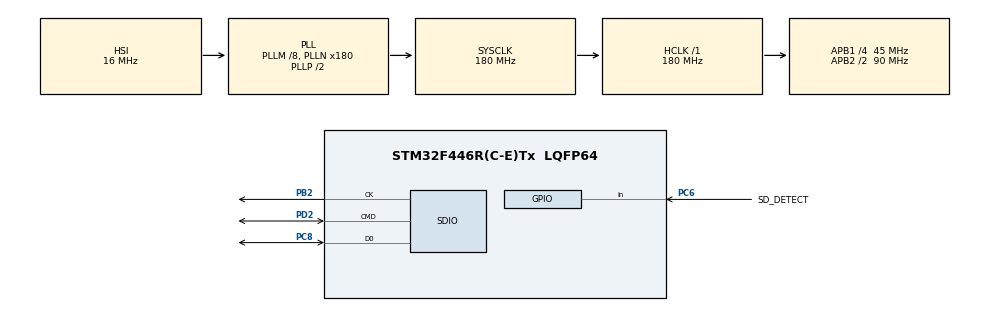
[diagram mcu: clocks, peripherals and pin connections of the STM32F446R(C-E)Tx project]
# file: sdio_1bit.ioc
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Dma.Request0=SDIO_RX
Dma.Request1=SDIO_TX
Dma.SDIO_RX.0.Direction=DMA_PERIPH_TO_MEMORY
Dma.SDIO_RX.0.FIFOMode=DMA_FIFOMODE_ENABLE
Dma.SDIO_RX.0.FIFOThreshold=DMA_FIFO_THRESHOLD_FULL
Dma.SDIO_RX.0.Instance=DMA2_Stream3
Dma.SDIO_RX.0.MemBurst=DMA_MBURST_INC4
Dma.SDIO_RX.0.MemDataAlignment=DMA_MDATAALIGN_WORD
Dma.SDIO_RX.0.MemInc=DMA_MINC_ENABLE
Dma.SDIO_RX.0.Mode=DMA_PFCTRL
Dma.SDIO_RX.0.PeriphBurst=DMA_PBURST_INC4
Dma.SDIO_RX.0.PeriphDataAlignment=DMA_PDATAALIGN_WORD
Dma.SDIO_RX.0.PeriphInc=DMA_PINC_DISABLE
Dma.SDIO_RX.0.Priority=DMA_PRIORITY_LOW
Dma.SDIO_TX.1.Direction=DMA_MEMORY_TO_PERIPH
Dma.SDIO_TX.1.FIFOMode=DMA_FIFOMODE_ENABLE
Dma.SDIO_TX.1.FIFOThreshold=DMA_FIFO_THRESHOLD_FULL
Dma.SDIO_TX.1.Instance=DMA2_Stream6
Dma.SDIO_TX.1.MemBurst=DMA_MBURST_INC4
Dma.SDIO_TX.1.MemDataAlignment=DMA_MDATAALIGN_WORD
Dma.SDIO_TX.1.MemInc=DMA_MINC_ENABLE
Dma.SDIO_TX.1.Mode=DMA_PFCTRL
Dma.SDIO_TX.1.PeriphBurst=DMA_PBURST_INC4
Dma.SDIO_TX.1.PeriphDataAlignment=DMA_PDATAALIGN_WORD
Dma.SDIO_TX.1.PeriphInc=DMA_PINC_DISABLE
Dma.SDIO_TX.1.Priority=DMA_PRIORITY_LOW
FATFS.BSP.number=1
FATFS._MAX_SS=4096
FATFS._USE_LFN=3
FATFS0.BSP.STBoard=false
FATFS0.BSP.api=Unknown
FATFS0.BSP.instance=PC6
FATFS0.BSP.ip=GPIO
FATFS0.BSP.mode=Input
FATFS0.BSP.name=Detect_SDIO
FATFS0.BSP.solution=PC6
Mcu.Family=STM32F4
Mcu.Name=STM32F446R(C-E)Tx
Mcu.Package=LQFP64
NVIC.DMA2_Stream3_IRQn=true\:0\:0\:false\:false\:true\:false\:true\:true
NVIC.DMA2_Stream6_IRQn=true\:0\:0\:false\:false\:true\:false\:true\:true
NVIC.PriorityGroup=NVIC_PRIORITYGROUP_4
PA13.Mode=Serial_Wire
PA13.Signal=SYS_JTMS-SWDIO
PA14.Mode=Serial_Wire
PA14.Signal=SYS_JTCK-SWCLK
PB2.Mode=SD_1_bit
PB2.Signal=SDIO_CK
PC6.GPIO_Label=SD_DETECT
PC6.GPIO_PuPd=GPIO_NOPULL
PC6.Signal=GPIO_Input
PC8.Mode=SD_1_bit
PC8.Signal=SDIO_D0
PD2.Mode=SD_1_bit
PD2.Signal=SDIO_CMD
ProjectManager.HeapSize=0x200
ProjectManager.StackSize=0x400
ProjectManager.TargetToolchain=STM32CubeIDE
RCC.AHBFreq_Value=180000000
RCC.APB1CLKDivider=RCC_HCLK_DIV4
RCC.APB1Freq_Value=45000000
RCC.APB1TimFreq_Value=90000000
RCC.APB2CLKDivider=RCC_HCLK_DIV2
RCC.APB2Freq_Value=90000000
RCC.APB2TimFreq_Value=180000000
RCC.CortexFreq_Value=180000000
RCC.HCLKFreq_Value=180000000
RCC.PLLM=8
RCC.PLLN=180
RCC.PLLQ=8
RCC.SYSCLKFreq_VALUE=180000000
RCC.SYSCLKSource=RCC_SYSCLKSOURCE_PLLCLK
RCC.USBFreq_Value=45000000
RCC.VCOOutputFreq_Value=360000000
SDIO.ClockDiv=10
VP_FATFS_VS_SDIO.Mode=SDIO
board=custom

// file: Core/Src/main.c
/* USER CODE BEGIN Header */
/**
  ******************************************************************************
  * @file           : main.c
  * @brief          : Main program body
  ******************************************************************************
  * @attention
  *
  * Copyright (c) 2024 STMicroelectronics.
  * All rights reserved.
  *
  * This software is licensed under terms that can be found in the LICENSE file
  * in the root directory of this software component.
  * If no LICENSE file comes with this software, it is provided AS-IS.
  *
  ******************************************************************************
  */
/* USER CODE END Header */
#include "main.h"
#include "fatfs.h"

/* USER CODE BEGIN Includes */
#include "stdio.h"
#include "sd.h"
/* USER CODE END Includes */

SD_HandleTypeDef hsd;
DMA_HandleTypeDef hdma_sdio_rx;
DMA_HandleTypeDef hdma_sdio_tx;

void SystemClock_Config(void);
static void MX_GPIO_Init(void);
static void MX_DMA_Init(void);
static void MX_SDIO_SD_Init(void);

/* USER CODE BEGIN 0 */
uint8_t buff[64];
/* USER CODE END 0 */

int main(void)
{

  /* MCU Configuration--------------------------------------------------------*/

  /* Reset of all peripherals, Initializes the Flash interface and the Systick. */
  HAL_Init();

  /* Configure the system clock */
  SystemClock_Config();

  /* Initialize all configured peripherals */
  MX_GPIO_Init();
  MX_DMA_Init();
  MX_SDIO_SD_Init();
  MX_FATFS_Init();
  /* USER CODE BEGIN 2 */
  sd_card_mount();
  sd_card_read("test.txt");
  sd_card_write("write.txt", "Joke, Cunning, and Revenge");
  sd_card_read("write.txt");
  sd_card_unmount();

  /* USER CODE END 2 */

  /* Infinite loop */
  while (1)
  {

  }
}

void SystemClock_Config(void)
{
  RCC_OscInitTypeDef RCC_OscInitStruct = {0};
  RCC_ClkInitTypeDef RCC_ClkInitStruct = {0};

  /** Configure the main internal regulator output voltage
  */
  __HAL_RCC_PWR_CLK_ENABLE();
  __HAL_PWR_VOLTAGESCALING_CONFIG(PWR_REGULATOR_VOLTAGE_SCALE1);

  /** Initializes the RCC Oscillators according to the specified parameters
  * in the RCC_OscInitTypeDef structure.
  */
  RCC_OscInitStruct.OscillatorType = RCC_OSCILLATORTYPE_HSI;
  RCC_OscInitStruct.HSIState = RCC_HSI_ON;
  RCC_OscInitStruct.HSICalibrationValue = RCC_HSICALIBRATION_DEFAULT;
  RCC_OscInitStruct.PLL.PLLState = RCC_PLL_ON;
  RCC_OscInitStruct.PLL.PLLSource = RCC_PLLSOURCE_HSI;
  RCC_OscInitStruct.PLL.PLLM = 8;
  RCC_OscInitStruct.PLL.PLLN = 180;
  RCC_OscInitStruct.PLL.PLLP = RCC_PLLP_DIV2;
  RCC_OscInitStruct.PLL.PLLQ = 8;
  RCC_OscInitStruct.PLL.PLLR = 2;
  if (HAL_RCC_OscConfig(&RCC_OscInitStruct) != HAL_OK)
  {
    Error_Handler();
  }

  /** Activate the Over-Drive mode
  */
  if (HAL_PWREx_EnableOverDrive() != HAL_OK)
  {
    Error_Handler();
  }

  /** Initializes the CPU, AHB and APB buses clocks
  */
  RCC_ClkInitStruct.ClockType = RCC_CLOCKTYPE_HCLK|RCC_CLOCKTYPE_SYSCLK
                              |RCC_CLOCKTYPE_PCLK1|RCC_CLOCKTYPE_PCLK2;
  RCC_ClkInitStruct.SYSCLKSource = RCC_SYSCLKSOURCE_PLLCLK;
  RCC_ClkInitStruct.AHBCLKDivider = RCC_SYSCLK_DIV1;
  RCC_ClkInitStruct.APB1CLKDivider = RCC_HCLK_DIV4;
  RCC_ClkInitStruct.APB2CLKDivider = RCC_HCLK_DIV2;

  if (HAL_RCC_ClockConfig(&RCC_ClkInitStruct, FLASH_LATENCY_5) != HAL_OK)
  {
    Error_Handler();
  }
}

static void MX_SDIO_SD_Init(void)
{

  hsd.Instance = SDIO;
  hsd.Init.ClockEdge = SDIO_CLOCK_EDGE_RISING;
  hsd.Init.ClockBypass = SDIO_CLOCK_BYPASS_DISABLE;
  hsd.Init.ClockPowerSave = SDIO_CLOCK_POWER_SAVE_DISABLE;
  hsd.Init.BusWide = SDIO_BUS_WIDE_1B;
  hsd.Init.HardwareFlowControl = SDIO_HARDWARE_FLOW_CONTROL_DISABLE;
  hsd.Init.ClockDiv = 10;

}

static void MX_DMA_Init(void)
{

  /* DMA controller clock enable */
  __HAL_RCC_DMA2_CLK_ENABLE();

  /* DMA interrupt init */
  /* DMA2_Stream3_IRQn interrupt configuration */
  HAL_NVIC_SetPriority(DMA2_Stream3_IRQn, 0, 0);
  HAL_NVIC_EnableIRQ(DMA2_Stream3_IRQn);
  /* DMA2_Stream6_IRQn interrupt configuration */
  HAL_NVIC_SetPriority(DMA2_Stream6_IRQn, 0, 0);
  HAL_NVIC_EnableIRQ(DMA2_Stream6_IRQn);

}

static void MX_GPIO_Init(void)
{
  GPIO_InitTypeDef GPIO_InitStruct = {0};

  /* GPIO Ports Clock Enable */
  __HAL_RCC_GPIOB_CLK_ENABLE();
  __HAL_RCC_GPIOC_CLK_ENABLE();
  __HAL_RCC_GPIOA_CLK_ENABLE();
  __HAL_RCC_GPIOD_CLK_ENABLE();

  /*Configure GPIO pin : SD_DETECT_Pin */
  GPIO_InitStruct.Pin = SD_DETECT_Pin;
  GPIO_InitStruct.Mode = GPIO_MODE_INPUT;
  GPIO_InitStruct.Pull = GPIO_NOPULL;
  HAL_GPIO_Init(SD_DETECT_GPIO_Port, &GPIO_InitStruct);

}

/* USER CODE BEGIN 4 */
int _write(int file, char *ptr, int len)
{
  (void)file;
  int DataIdx;

  for (DataIdx = 0; DataIdx < len; DataIdx++)
  {
    ITM_SendChar(*ptr++);
  }
  return len;
}
/* USER CODE END 4 */

void Error_Handler(void)
{
  __disable_irq();
  while (1)
  {
  }
}
